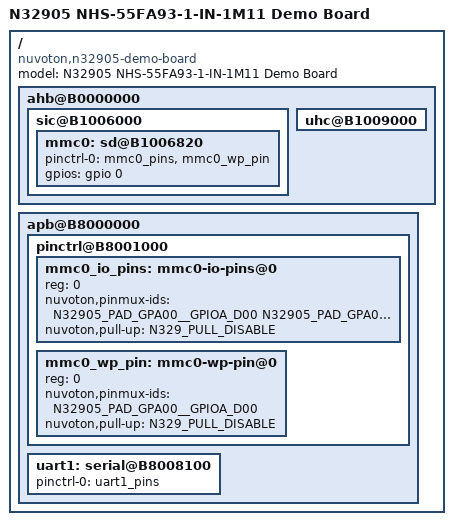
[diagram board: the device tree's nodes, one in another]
/*
 * Copyright (C) 2014 Michael P. Thompson, Inc. All Rights Reserved.
 *
 * This program is free software; you can redistribute it and/or modify
 * it under the terms of the GNU General Public License as published by
 * the Free Software Foundation; either version 2 of the License, or
 * (at your option) any later version.
 *
 * This program is distributed in the hope that it will be useful,
 * but WITHOUT ANY WARRANTY; without even the implied warranty of
 * MERCHANTABILITY or FITNESS FOR A PARTICULAR PURPOSE.  See the
 * GNU General Public License for more details.
 *
 * You should have received a copy of the GNU General Public License along
 * with this program; if not, write to the Free Software Foundation, Inc.,
 * 51 Franklin Street, Fifth Floor, Boston, MA 02110-1301 USA.
 */

/dts-v1/;
#include "n32905.dtsi"

/ {
	model = "N32905 NHS-55FA93-1-IN-1M11 Demo Board";
	compatible = "nuvoton,n32905-demo-board", "nuvoton,n32905", "nuvoton,n329";

	ahb@B0000000 {
		sic@B1006000 {
			status = "okay";

			mmc0: sd@B1006820 {
				pinctrl-names = "default";
				pinctrl-0 = <&mmc0_pins &mmc0_wp_pin>;
				gpios = <&gpio 0 0>;
				status = "okay";
			};
		};

		uhc@B1009000 {
			status = "okay";
		};
	};

	apb@B8000000 {
		pinctrl@B8001000 {
			mmc0_io_pins: mmc0-io-pins@0 {
				reg = <0>;
				nuvoton,pinmux-ids = <
					N32905_PAD_GPA00__GPIOA_D00
					N32905_PAD_GPA01__GPIOA_D01
				>;
				nuvoton,pull-up = <N329_PULL_DISABLE>;
			};

			mmc0_wp_pin: mmc0-wp-pin@0 {
				reg = <0>;
				nuvoton,pinmux-ids = <
					N32905_PAD_GPA00__GPIOA_D00
				>;
				nuvoton,pull-up = <N329_PULL_DISABLE>;
			};
		};
		uart1: serial@B8008100 {
			pinctrl-names = "default";
			pinctrl-0 = <&uart1_pins>;
			status = "okay";
		};
	};
};

